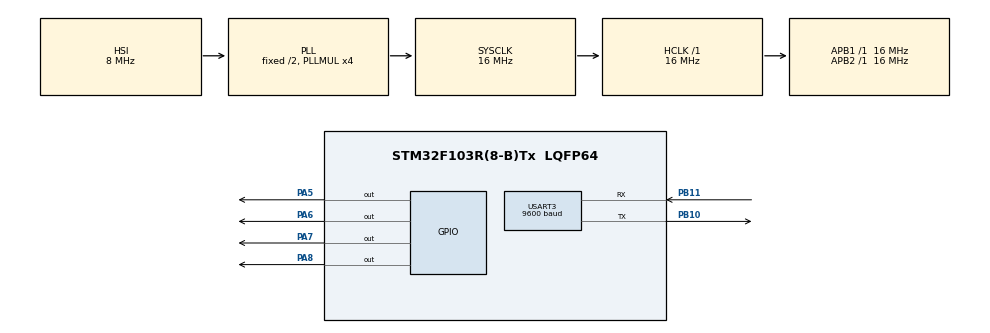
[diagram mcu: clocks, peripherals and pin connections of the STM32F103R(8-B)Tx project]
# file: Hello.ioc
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Mcu.Family=STM32F1
Mcu.Name=STM32F103R(8-B)Tx
Mcu.Package=LQFP64
NVIC.PriorityGroup=NVIC_PRIORITYGROUP_4
PA13.Mode=Serial_Wire
PA13.Signal=SYS_JTMS-SWDIO
PA14.Mode=Serial_Wire
PA14.Signal=SYS_JTCK-SWCLK
PA5.PinState=GPIO_PIN_SET
PA5.Signal=GPIO_Output
PA6.PinState=GPIO_PIN_SET
PA6.Signal=GPIO_Output
PA7.PinState=GPIO_PIN_SET
PA7.Signal=GPIO_Output
PA8.PinState=GPIO_PIN_SET
PA8.Signal=GPIO_Output
PB10.Mode=Asynchronous
PB10.Signal=USART3_TX
PB11.Mode=Asynchronous
PB11.Signal=USART3_RX
ProjectManager.HeapSize=0x200
ProjectManager.StackSize=0x400
ProjectManager.TargetToolchain=Makefile
RCC.AHBFreq_Value=16000000
RCC.APB1Freq_Value=16000000
RCC.APB1TimFreq_Value=16000000
RCC.APB2Freq_Value=16000000
RCC.APB2TimFreq_Value=16000000
RCC.HCLKFreq_Value=16000000
RCC.PLLMUL=RCC_PLL_MUL4
RCC.SYSCLKFreq_VALUE=16000000
RCC.SYSCLKSource=RCC_SYSCLKSOURCE_PLLCLK
RCC.USBFreq_Value=16000000
USART3.BaudRate=9600
USART3.VirtualMode=VM_ASYNC
board=custom

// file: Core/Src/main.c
/* USER CODE BEGIN Header */
/**
  ******************************************************************************
  * @file           : main.c
  * @brief          : Main program body
  ******************************************************************************
  * @attention
  *
  * Copyright (c) 2026 STMicroelectronics.
  * All rights reserved.
  *
  * This software is licensed under terms that can be found in the LICENSE file
  * in the root directory of this software component.
  * If no LICENSE file comes with this software, it is provided AS-IS.
  *
  ******************************************************************************
  */
/* USER CODE END Header */
#include "main.h"

UART_HandleTypeDef huart3;

void SystemClock_Config(void);
static void MX_GPIO_Init(void);
static void MX_USART3_UART_Init(void);

int main(void)
{

  /* MCU Configuration--------------------------------------------------------*/

  /* Reset of all peripherals, Initializes the Flash interface and the Systick. */
  HAL_Init();

  /* Configure the system clock */
  SystemClock_Config();

  /* Initialize all configured peripherals */
  MX_GPIO_Init();
  MX_USART3_UART_Init();
  /* USER CODE BEGIN 2 */
  /* 無其他初始化 */
  /* USER CODE END 2 */

  /* Infinite loop */
  /* USER CODE BEGIN WHILE */
  while (1)
  {
    /* LED 閃爍 */
    HAL_GPIO_WritePin(GPIOA, GPIO_PIN_5, GPIO_PIN_SET);   // LED ON
    HAL_GPIO_WritePin(GPIOA, GPIO_PIN_6, GPIO_PIN_SET);   // LED ON
    HAL_GPIO_WritePin(GPIOA, GPIO_PIN_7, GPIO_PIN_RESET);   // LED ON

      // 發送字串到 UART1
    char *msg_on = "LED ON\r\n";
    HAL_UART_Transmit(&huart3, (uint8_t*)msg_on, 8, 100);

    HAL_Delay(500);                                        // 延遲 500 ms
    HAL_GPIO_WritePin(GPIOA, GPIO_PIN_5, GPIO_PIN_RESET); // LED OFF
    HAL_GPIO_WritePin(GPIOA, GPIO_PIN_6, GPIO_PIN_RESET);   // LED ON
    HAL_GPIO_WritePin(GPIOA, GPIO_PIN_7, GPIO_PIN_SET);   // LED ON

    char *msg_off = "LED OFF\r\n";
    HAL_UART_Transmit(&huart3, (uint8_t*)msg_off, 9, 100);

    HAL_Delay(500);                                        // 延遲 500 ms
  }
    /* USER CODE END WHILE */

    /* USER CODE BEGIN 3 */
  /* 不會到這裡 */
  /* USER CODE END 3 */
}

void SystemClock_Config(void)
{
  RCC_OscInitTypeDef RCC_OscInitStruct = {0};
  RCC_ClkInitTypeDef RCC_ClkInitStruct = {0};

  /** Initializes the RCC Oscillators according to the specified parameters
  * in the RCC_OscInitTypeDef structure.
  */
  RCC_OscInitStruct.OscillatorType = RCC_OSCILLATORTYPE_HSI;
  RCC_OscInitStruct.HSIState = RCC_HSI_ON;
  RCC_OscInitStruct.HSICalibrationValue = RCC_HSICALIBRATION_DEFAULT;
  RCC_OscInitStruct.PLL.PLLState = RCC_PLL_ON;
  RCC_OscInitStruct.PLL.PLLSource = RCC_PLLSOURCE_HSI_DIV2;
  RCC_OscInitStruct.PLL.PLLMUL = RCC_PLL_MUL4;
  if (HAL_RCC_OscConfig(&RCC_OscInitStruct) != HAL_OK)
  {
    Error_Handler();
  }

  /** Initializes the CPU, AHB and APB buses clocks
  */
  RCC_ClkInitStruct.ClockType = RCC_CLOCKTYPE_HCLK|RCC_CLOCKTYPE_SYSCLK
                              |RCC_CLOCKTYPE_PCLK1|RCC_CLOCKTYPE_PCLK2;
  RCC_ClkInitStruct.SYSCLKSource = RCC_SYSCLKSOURCE_PLLCLK;
  RCC_ClkInitStruct.AHBCLKDivider = RCC_SYSCLK_DIV1;
  RCC_ClkInitStruct.APB1CLKDivider = RCC_HCLK_DIV1;
  RCC_ClkInitStruct.APB2CLKDivider = RCC_HCLK_DIV1;

  if (HAL_RCC_ClockConfig(&RCC_ClkInitStruct, FLASH_LATENCY_0) != HAL_OK)
  {
    Error_Handler();
  }
}

static void MX_USART3_UART_Init(void)
{

  huart3.Instance = USART3;
  huart3.Init.BaudRate = 9600;
  huart3.Init.WordLength = UART_WORDLENGTH_8B;
  huart3.Init.StopBits = UART_STOPBITS_1;
  huart3.Init.Parity = UART_PARITY_NONE;
  huart3.Init.Mode = UART_MODE_TX_RX;
  huart3.Init.HwFlowCtl = UART_HWCONTROL_NONE;
  huart3.Init.OverSampling = UART_OVERSAMPLING_16;
  if (HAL_UART_Init(&huart3) != HAL_OK)
  {
    Error_Handler();
  }

}

static void MX_GPIO_Init(void)
{
  GPIO_InitTypeDef GPIO_InitStruct = {0};

  /* GPIO Ports Clock Enable */
  __HAL_RCC_GPIOA_CLK_ENABLE();
  __HAL_RCC_GPIOB_CLK_ENABLE();

  /*Configure GPIO pin Output Level */
  HAL_GPIO_WritePin(GPIOA, GPIO_PIN_5|GPIO_PIN_6|GPIO_PIN_7|GPIO_PIN_8, GPIO_PIN_SET);

  /*Configure GPIO pins : PA5 PA6 PA7 PA8 */
  GPIO_InitStruct.Pin = GPIO_PIN_5|GPIO_PIN_6|GPIO_PIN_7|GPIO_PIN_8;
  GPIO_InitStruct.Mode = GPIO_MODE_OUTPUT_PP;
  GPIO_InitStruct.Pull = GPIO_NOPULL;
  GPIO_InitStruct.Speed = GPIO_SPEED_FREQ_LOW;
  HAL_GPIO_Init(GPIOA, &GPIO_InitStruct);

}

void Error_Handler(void)
{
  __disable_irq();
  while (1)
  {
  }
}
